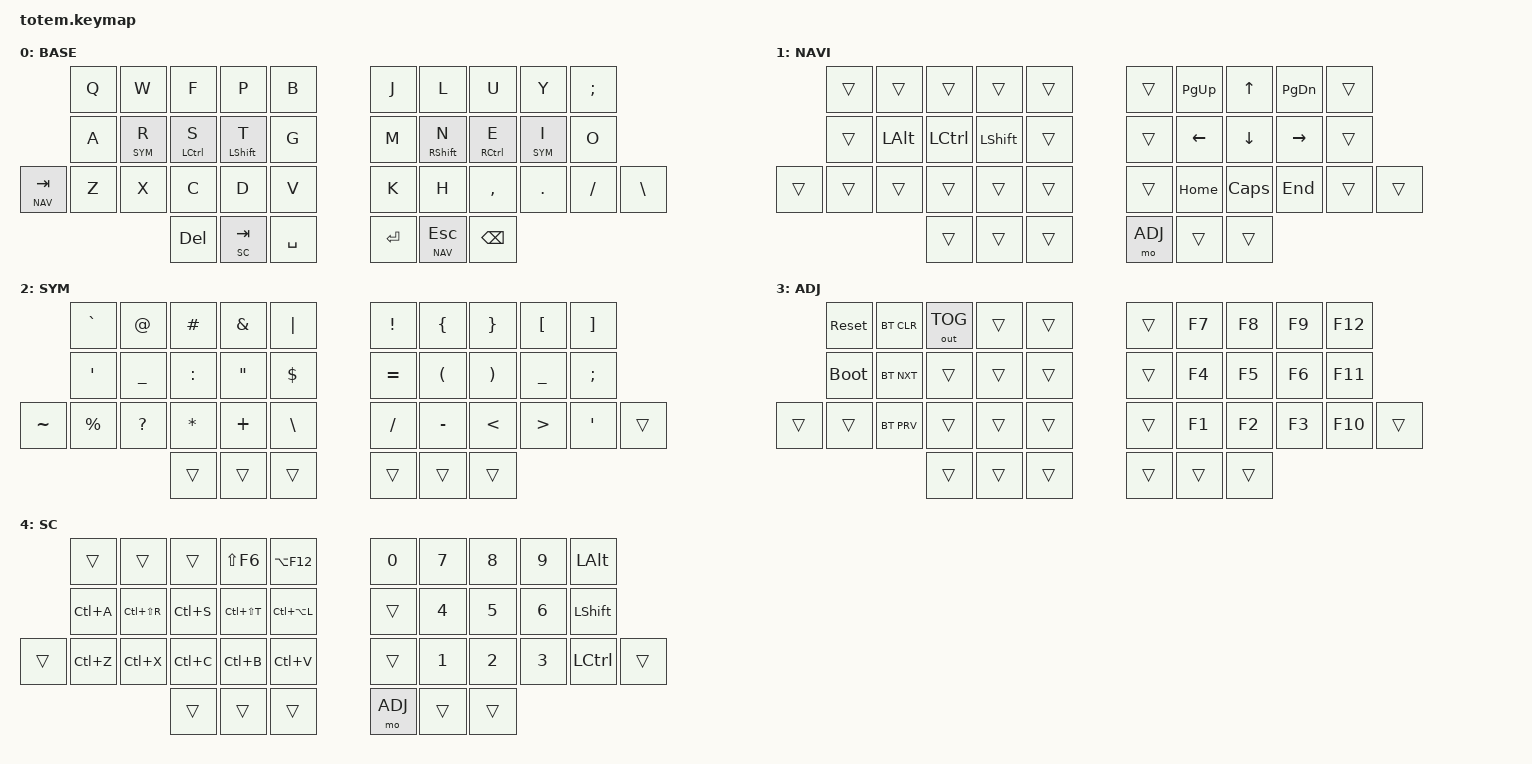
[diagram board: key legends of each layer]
//
//                                                        ▀▀▀▀▀     ▀▀▀▀▀          ▀▀█▀▀
//                                                        ▄▀▀▀▄  ▄  ▄▀▀▀▄  ▄  ▄▀▀▀▄  █  ▄▀▀▀▄
//                                                        █   █  █  █   █  █  █   █  █  █   █
//                                                         ▀▀▀   █   ▀▀▀   █   ▀▀▀   ▀   ▀▀▀
//                                                               █      ▄▄▄█▄▄▄    █   █  
//                                                               ▀      █  █  █     █▄█
//                                                             ▀▀▀▀▀    █  █  █      ▀
//                                                                      ▀  ▀  ▀
//
// ▄▄▄▄▄▄▄▄▄▄▄▄▄▄▄▄▄▄▄▄▄▄▄▄▄▄▄▄▄▄▄▄▄▄▄▄▄▄▄▄▄▄▄▄▄▄▄▄▄▄▄▄▄▄▄▄▄▄▄▄▄▄▄▄▄▄▄▄▄▄▄▄▄▄▄▄▄▄▄▄▄▄▄▄▄▄▄▄▄▄▄▄▄▄▄▄▄▄▄▄▄▄▄▄▄▄▄▄▄▄▄▄▄▄▄▄▄▄▄▄▄▄▄▄▄▄▄▄▄▄▄▄▄▄▄▄▄▄▄▄▄▄▄▄▄▄▄▄▄

#include <behaviors.dtsi>
#include <dt-bindings/zmk/bt.h>
#include <dt-bindings/zmk/keys.h>
#include <dt-bindings/zmk/outputs.h>

#define BASE 0
#define NAV  1
#define SYM  2
#define ADJ  3
#define SC   4

&mt {
    quick-tap-ms = <100>;
    global-quick-tap;
    flavor = "tap-preferred";
    tapping-term-ms = <170>;
};

/ {
    combos {
        compatible = "zmk,combos";

            combo_left_gui {
                timeout-ms = <50>;
                key-positions = <0 1>;
                bindings = <&kp LGUI>;
            };
            combo_right_gui {
                timeout-ms = <50>;
                key-positions = <8 9>;
                bindings = <&kp LGUI>;
            };
            combo_left_alt {
                timeout-ms = <50>;
                key-positions = <22 23>;
                bindings = <&kp LALT>;
            };
            combo_right_alt {
                timeout-ms = <50>;
                key-positions = <28 29>;
                bindings = <&kp LALT>;
            };
    };

    macros {
    };

    keymap {
        compatible = "zmk,keymap";

        // ▄▄▄▄▄▄▄▄▄▄▄▄▄▄▄▄▄▄▄▄▄▄▄▄▄▄▄▄▄▄▄▄▄▄▄▄▄▄▄▄▄▄▄▄▄▄▄▄▄▄▄▄▄▄▄▄▄▄▄▄▄▄▄▄▄▄▄▄▄▄▄▄▄▄▄▄▄▄▄▄▄▄▄▄▄▄▄▄▄▄▄▄▄▄▄▄▄▄▄▄▄▄▄▄▄▄▄▄▄▄▄▄▄▄▄▄▄▄▄▄▄▄▄▄▄▄▄▄▄▄▄▄▄▄▄▄▄▄▄▄▄▄▄▄▄▄▄▄▄

        base_layer {
            // ┏━━━━━━━━━━━━━━━━━━━━━━━━━━━━━━━━━━━━━━━┓

            label = "BASE";

            // ┗━━━━━━━━━━━━━━━━━━━━━━━━━━━━━━━━━━━━━━━┛
            //             ┏━━━━━━━━━━━┳━━━━━━━━━━━┳━━━━━━━━━━━┳━━━━━━━━━━━┳━━━━━━━━━━━┓   ┏━━━━━━━━━━━┳━━━━━━━━━━━┳━━━━━━━━━━━┳━━━━━━━━━━━┳━━━━━━━━━━━┓
            //             ┃     Q     ┃     W     ┃     F     ┃     P     ┃     B     ┃   ┃     J     ┃     L     ┃     U     ┃     Y     ┃     ;     ┃
            //             ┣━━━━━━━━━━━╋━━━━━━━━━━━╋━━━━━━━━━━━╋━━━━━━━━━━━╋━━━━━━━━━━━┫   ┣━━━━━━━━━━━╋━━━━━━━━━━━╋━━━━━━━━━━━╋━━━━━━━━━━━╋━━━━━━━━━━━┫
            //             ┃     A     ┃    R $    ┃    S ⎈    ┃    T ⇧    ┃     G     ┃   ┃     M     ┃    N ⇧    ┃    E ⎈    ┃    I $    ┃     O     ┃
            // ┏━━━━━━━━━━━╋━━━━━━━━━━━╋━━━━━━━━━━━╋━━━━━━━━━━━╋━━━━━━━━━━━╋━━━━━━━━━━━┫   ┣━━━━━━━━━━━╋━━━━━━━━━━━╋━━━━━━━━━━━╋━━━━━━━━━━━╋━━━━━━━━━━━╋━━━━━━━━━━━┓
            // ┃    TAB    ┃     Z     ┃     X     ┃     C     ┃     D     ┃     V     ┃   ┃     K     ┃     H     ┃     ,     ┃     .     ┃     /     ┃     \     ┃
            // ┗━━━━━━━━━━━┻━━━━━━━━━━━┻━━━━━━━━━━━╋━━━━━━━━━━━╋━━━━━━━━━━━╋━━━━━━━━━━━┫   ┣━━━━━━━━━━━╋━━━━━━━━━━━╋━━━━━━━━━━━╋━━━━━━━━━━━┻━━━━━━━━━━━┻━━━━━━━━━━━┛
            //                                     ┃    DEL    ┃ TAB / SC  ┃    SPC    ┃   ┃   ENTER   ┃ ESC / NAV ┃   BSPC    ┃
            //                                     ┗━━━━━━━━━━━┻━━━━━━━━━━━┻━━━━━━━━━━━┛   ┗━━━━━━━━━━━┻━━━━━━━━━━━┻━━━━━━━━━━━┛

            bindings = <
        &kp Q       &kp W       &kp F       &kp P       &kp B                   &kp J       &kp L       &kp U       &kp Y       &kp SEMI
        &kp A       &lt SYM R   &mt LCTRL S &mt LSHFT T &kp G                   &kp M       &mt RSHFT N &mt RCTRL E &lt SYM I   &kp O
&lt NAV TAB &kp Z   &kp X       &kp C       &kp D       &kp V                   &kp K       &kp H       &kp COMMA   &kp DOT     &kp FSLH    &kp BSLH
                                &kp DEL     &lt SC TAB  &kp SPACE               &kp RET     &lt NAV ESC &kp BSPC
            >;
        };

        // ▄▄▄▄▄▄▄▄▄▄▄▄▄▄▄▄▄▄▄▄▄▄▄▄▄▄▄▄▄▄▄▄▄▄▄▄▄▄▄▄▄▄▄▄▄▄▄▄▄▄▄▄▄▄▄▄▄▄▄▄▄▄▄▄▄▄▄▄▄▄▄▄▄▄▄▄▄▄▄▄▄▄▄▄▄▄▄▄▄▄▄▄▄▄▄▄▄▄▄▄▄▄▄▄▄▄▄▄▄▄▄▄▄▄▄▄▄▄▄▄▄▄▄▄▄▄▄▄▄▄▄▄▄▄▄▄▄▄▄▄▄▄▄▄▄▄▄▄▄

        nav_layer {
            // ┏━━━━━━━━━━━━━━━━━━━━━━━━━━━━━━━━━━━━━━━┓

            label = "NAVI";

            // ┗━━━━━━━━━━━━━━━━━━━━━━━━━━━━━━━━━━━━━━━┛
            //             ┏━━━━━━━━━━━┳━━━━━━━━━━━┳━━━━━━━━━━━┳━━━━━━━━━━━┳━━━━━━━━━━━┓   ┏━━━━━━━━━━━┳━━━━━━━━━━━┳━━━━━━━━━━━┳━━━━━━━━━━━┳━━━━━━━━━━━┓
            //             ┃           ┃           ┃           ┃           ┃           ┃   ┃           ┃  PAGE UP  ┃    UP     ┃ PAGE DOWN ┃           ┃
            //             ┣━━━━━━━━━━━╋━━━━━━━━━━━╋━━━━━━━━━━━╋━━━━━━━━━━━╋━━━━━━━━━━━┫   ┣━━━━━━━━━━━╋━━━━━━━━━━━╋━━━━━━━━━━━╋━━━━━━━━━━━╋━━━━━━━━━━━┫
            //             ┃           ┃    ALT    ┃  CONTROL  ┃   SHIFT   ┃           ┃   ┃           ┃    LEFT   ┃   DOWN    ┃   RIGHT   ┃           ┃
            // ┏━━━━━━━━━━━╋━━━━━━━━━━━╋━━━━━━━━━━━╋━━━━━━━━━━━╋━━━━━━━━━━━╋━━━━━━━━━━━┫   ┣━━━━━━━━━━━╋━━━━━━━━━━━╋━━━━━━━━━━━╋━━━━━━━━━━━╋━━━━━━━━━━━╋━━━━━━━━━━━┓
            // ┃           ┃           ┃           ┃           ┃           ┃           ┃   ┃           ┃    HOME   ┃ CAPS LOCK ┃    END    ┃           ┃           ┃
            // ┗━━━━━━━━━━━┻━━━━━━━━━━━┻━━━━━━━━━━━╋━━━━━━━━━━━╋━━━━━━━━━━━╋━━━━━━━━━━━┫   ┣━━━━━━━━━━━╋━━━━━━━━━━━╋━━━━━━━━━━━╋━━━━━━━━━━━┻━━━━━━━━━━━┻━━━━━━━━━━━┛
            //                                     ┃           ┃           ┃           ┃   ┃ Layer ADJ ┃           ┃           ┃
            //                                     ┗━━━━━━━━━━━┻━━━━━━━━━━━┻━━━━━━━━━━━┛   ┗━━━━━━━━━━━┻━━━━━━━━━━━┻━━━━━━━━━━━┛

            bindings = <
        &trans      &trans      &trans      &trans      &trans                  &trans      &kp PG_UP   &kp UP      &kp PG_DN   &trans      
        &trans      &kp LALT    &kp LCTRL   &kp LSHIFT  &trans                  &trans      &kp LEFT    &kp DOWN    &kp RIGHT   &trans      
&trans  &trans      &trans      &trans      &trans      &trans                  &trans      &kp HOME    &kp CAPS    &kp END     &trans      &trans      
                                &trans      &trans      &trans                  &mo ADJ     &trans      &trans
            >;
        };

        // ▄▄▄▄▄▄▄▄▄▄▄▄▄▄▄▄▄▄▄▄▄▄▄▄▄▄▄▄▄▄▄▄▄▄▄▄▄▄▄▄▄▄▄▄▄▄▄▄▄▄▄▄▄▄▄▄▄▄▄▄▄▄▄▄▄▄▄▄▄▄▄▄▄▄▄▄▄▄▄▄▄▄▄▄▄▄▄▄▄▄▄▄▄▄▄▄▄▄▄▄▄▄▄▄▄▄▄▄▄▄▄▄▄▄▄▄▄▄▄▄▄▄▄▄▄▄▄▄▄▄▄▄▄▄▄▄▄▄▄▄▄▄▄▄▄▄▄▄▄

        sim_layer {
            // ┏━━━━━━━━━━━━━━━━━━━━━━━━━━━━━━━━━━━━━━━┓

            label = "SYM";

            // ┗━━━━━━━━━━━━━━━━━━━━━━━━━━━━━━━━━━━━━━━┛
            //             ┏━━━━━━━━━━━┳━━━━━━━━━━━┳━━━━━━━━━━━┳━━━━━━━━━━━┳━━━━━━━━━━━┓   ┏━━━━━━━━━━━┳━━━━━━━━━━━┳━━━━━━━━━━━┳━━━━━━━━━━━┳━━━━━━━━━━━┓
            //             ┃     `     ┃     @     ┃     #     ┃     &     ┃     |     ┃   ┃     !     ┃     {     ┃     }     ┃     [     ┃     ]     ┃
            //             ┣━━━━━━━━━━━╋━━━━━━━━━━━╋━━━━━━━━━━━╋━━━━━━━━━━━╋━━━━━━━━━━━┫   ┣━━━━━━━━━━━╋━━━━━━━━━━━╋━━━━━━━━━━━╋━━━━━━━━━━━╋━━━━━━━━━━━┫
            //             ┃     '     ┃     _     ┃     :     ┃     "     ┃     $     ┃   ┃     =     ┃     (     ┃     )     ┃     _     ┃     ;     ┃
            // ┏━━━━━━━━━━━╋━━━━━━━━━━━╋━━━━━━━━━━━╋━━━━━━━━━━━╋━━━━━━━━━━━╋━━━━━━━━━━━┫   ┣━━━━━━━━━━━╋━━━━━━━━━━━╋━━━━━━━━━━━╋━━━━━━━━━━━╋━━━━━━━━━━━╋━━━━━━━━━━━┓
            // ┃     ~     ┃     %     ┃     ?     ┃     *     ┃     +     ┃     \     ┃   ┃     /     ┃     -     ┃     <     ┃     >     ┃     '     ┃           ┃
            // ┗━━━━━━━━━━━┻━━━━━━━━━━━┻━━━━━━━━━━━╋━━━━━━━━━━━╋━━━━━━━━━━━╋━━━━━━━━━━━┫   ┣━━━━━━━━━━━╋━━━━━━━━━━━╋━━━━━━━━━━━╋━━━━━━━━━━━┻━━━━━━━━━━━┻━━━━━━━━━━━┛
            //                                     ┃           ┃           ┃           ┃   ┃           ┃           ┃           ┃
            //                                     ┗━━━━━━━━━━━┻━━━━━━━━━━━┻━━━━━━━━━━━┛   ┗━━━━━━━━━━━┻━━━━━━━━━━━┻━━━━━━━━━━━┛
            bindings = <
        &kp GRAVE   &kp AT      &kp HASH    &kp AMPS    &kp PIPE                &kp EXCL    &kp LBRC    &kp RBRC    &kp LBKT    &kp RBKT      
        &kp SQT     &kp UNDER   &kp COLON   &kp DQT     &kp DLLR                &kp EQUAL   &kp LPAR    &kp RPAR    &kp UNDER   &kp SEMI 
&kp TILDE &kp PRCNT &kp QMARK   &kp STAR    &kp PLUS    &kp BSLH                &kp SLASH   &kp MINUS   &kp LT      &kp GT      &kp SQT     &trans         
                                &trans      &trans      &trans                  &trans      &trans      &trans      
            >;
        };

        // ▄▄▄▄▄▄▄▄▄▄▄▄▄▄▄▄▄▄▄▄▄▄▄▄▄▄▄▄▄▄▄▄▄▄▄▄▄▄▄▄▄▄▄▄▄▄▄▄▄▄▄▄▄▄▄▄▄▄▄▄▄▄▄▄▄▄▄▄▄▄▄▄▄▄▄▄▄▄▄▄▄▄▄▄▄▄▄▄▄▄▄▄▄▄▄▄▄▄▄▄▄▄▄▄▄▄▄▄▄▄▄▄▄▄▄▄▄▄▄▄▄▄▄▄▄▄▄▄▄▄▄▄▄▄▄▄▄▄▄▄▄▄▄▄▄▄▄▄▄

        adjust_layer {
            // ┏━━━━━━━━━━━━━━━━━━━━━━━━━━━━━━━━━━━━━━━┓

            label = "ADJ";

            // ┗━━━━━━━━━━━━━━━━━━━━━━━━━━━━━━━━━━━━━━━┛
            //             ┏━━━━━━━━━━━┳━━━━━━━━━━━┳━━━━━━━━━━━┳━━━━━━━━━━━┳━━━━━━━━━━━┓   ┏━━━━━━━━━━━┳━━━━━━━━━━━┳━━━━━━━━━━━┳━━━━━━━━━━━┳━━━━━━━━━━━┓
            //             ┃ RESET ALL ┃ BT CLEAR  ┃  OUT TOG  ┃           ┃           ┃   ┃           ┃    F7     ┃    F8     ┃    F9     ┃    F12    ┃
            //             ┣━━━━━━━━━━━╋━━━━━━━━━━━╋━━━━━━━━━━━╋━━━━━━━━━━━╋━━━━━━━━━━━┫   ┣━━━━━━━━━━━╋━━━━━━━━━━━╋━━━━━━━━━━━╋━━━━━━━━━━━╋━━━━━━━━━━━┫
            //             ┃ BOOTLOAD  ┃ BT NEXT   ┃           ┃           ┃           ┃   ┃           ┃    F4     ┃    F5     ┃    F6     ┃    F11    ┃
            // ┏━━━━━━━━━━━╋━━━━━━━━━━━╋━━━━━━━━━━━╋━━━━━━━━━━━╋━━━━━━━━━━━╋━━━━━━━━━━━┫   ┣━━━━━━━━━━━╋━━━━━━━━━━━╋━━━━━━━━━━━╋━━━━━━━━━━━╋━━━━━━━━━━━╋━━━━━━━━━━━┓
            // ┃           ┃           ┃ BT PREV   ┃           ┃           ┃           ┃   ┃           ┃    F1     ┃    F2     ┃    F3     ┃    F10    ┃           ┃
            // ┗━━━━━━━━━━━┻━━━━━━━━━━━┻━━━━━━━━━━━╋━━━━━━━━━━━╋━━━━━━━━━━━╋━━━━━━━━━━━┫   ┣━━━━━━━━━━━╋━━━━━━━━━━━╋━━━━━━━━━━━╋━━━━━━━━━━━┻━━━━━━━━━━━┻━━━━━━━━━━━┛
            //                                     ┃           ┃           ┃           ┃   ┃           ┃           ┃           ┃
            //                                     ┗━━━━━━━━━━━┻━━━━━━━━━━━┻━━━━━━━━━━━┛   ┗━━━━━━━━━━━┻━━━━━━━━━━━┻━━━━━━━━━━━┛

            bindings = <
        &sys_reset   &bt BT_CLR  &out OUT_TOG  &trans  &trans                &trans  &kp F7  &kp F8  &kp F9  &kp F12
        &bootloader  &bt BT_NXT  &trans        &trans  &trans                &trans  &kp F4  &kp F5  &kp F6  &kp F11
&trans  &trans       &bt BT_PRV  &trans        &trans  &trans                &trans  &kp F1  &kp F2  &kp F3  &kp F10  &trans
                                 &trans        &trans  &trans                &trans  &trans  &trans
            >;
        };

        // ▄▄▄▄▄▄▄▄▄▄▄▄▄▄▄▄▄▄▄▄▄▄▄▄▄▄▄▄▄▄▄▄▄▄▄▄▄▄▄▄▄▄▄▄▄▄▄▄▄▄▄▄▄▄▄▄▄▄▄▄▄▄▄▄▄▄▄▄▄▄▄▄▄▄▄▄▄▄▄▄▄▄▄▄▄▄▄▄▄▄▄▄▄▄▄▄▄▄▄▄▄▄▄▄▄▄▄▄▄▄▄▄▄▄▄▄▄▄▄▄▄▄▄▄▄▄▄▄▄▄▄▄▄▄▄▄▄▄▄▄▄▄▄▄▄▄▄▄▄

        shortcut_layer {
            // ┏━━━━━━━━━━━━━━━━━━━━━━━━━━━━━━━━━━━━━━━┓

            label = "SC";

            // ┗━━━━━━━━━━━━━━━━━━━━━━━━━━━━━━━━━━━━━━━┛
            //             ┏━━━━━━━━━━━┳━━━━━━━━━━━┳━━━━━━━━━━━┳━━━━━━━━━━━┳━━━━━━━━━━━┓   ┏━━━━━━━━━━━┳━━━━━━━━━━━┳━━━━━━━━━━━┳━━━━━━━━━━━┳━━━━━━━━━━━┓
            //             ┃           ┃           ┃           ┃ SHIFT + F6┃ ALT + F12 ┃   ┃     0     ┃     7     ┃     8     ┃     9     ┃    ALT    ┃
            //             ┣━━━━━━━━━━━╋━━━━━━━━━━━╋━━━━━━━━━━━╋━━━━━━━━━━━╋━━━━━━━━━━━┫   ┣━━━━━━━━━━━╋━━━━━━━━━━━╋━━━━━━━━━━━╋━━━━━━━━━━━╋━━━━━━━━━━━┫
            //             ┃ CTRL + A  ┃CTRL+SHFT+R┃ CTRL + S  ┃CTRL+SHFT+T┃ CTRL+ALT+L┃   ┃           ┃     4     ┃     5     ┃     6     ┃   SHIFT   ┃
            // ┏━━━━━━━━━━━╋━━━━━━━━━━━╋━━━━━━━━━━━╋━━━━━━━━━━━╋━━━━━━━━━━━╋━━━━━━━━━━━┫   ┣━━━━━━━━━━━╋━━━━━━━━━━━╋━━━━━━━━━━━╋━━━━━━━━━━━╋━━━━━━━━━━━╋━━━━━━━━━━━┓
            // ┃           ┃ CTRL + Z  ┃ CTRL + X  ┃ CTRL + C  ┃ CTRL + B  ┃ CTRL + V  ┃   ┃           ┃     1     ┃     2     ┃     3     ┃  CONTROL  ┃           ┃
            // ┗━━━━━━━━━━━┻━━━━━━━━━━━┻━━━━━━━━━━━╋━━━━━━━━━━━╋━━━━━━━━━━━╋━━━━━━━━━━━┫   ┣━━━━━━━━━━━╋━━━━━━━━━━━╋━━━━━━━━━━━╋━━━━━━━━━━━┻━━━━━━━━━━━┻━━━━━━━━━━━┛
            //                                     ┃           ┃           ┃           ┃   ┃    ADJ    ┃           ┃           ┃
            //                                     ┗━━━━━━━━━━━┻━━━━━━━━━━━┻━━━━━━━━━━━┛   ┗━━━━━━━━━━━┻━━━━━━━━━━━┻━━━━━━━━━━━┛

            bindings = <
        &trans      &trans       &trans     &kp LS(F6)   &kp LA(F12)         &kp N0      &kp N7     &kp N8     &kp N9     &kp LALT
        &kp LC(A)   &kp LC(LS(R))&kp LC(S)  &kp LC(LS(T))&kp LC(LA(L))       &trans      &kp N4     &kp N5     &kp N6     &kp LSHFT  
&trans  &kp LC(Z)   &kp LC(X)    &kp LC(C)  &kp LC(B)    &kp LC(V)           &trans      &kp N1     &kp N2     &kp N3     &kp LCTRL     &trans      
                                 &trans     &trans       &trans              &mo ADJ     &trans     &trans
                        >;
                };
        };
};
